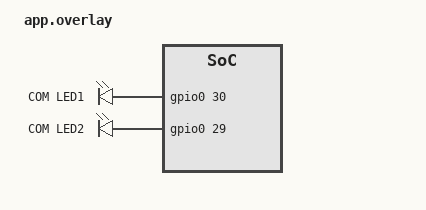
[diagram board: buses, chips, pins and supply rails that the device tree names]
/ {
    chosen {
        zephyr,sram = &sram0;
        zephyr,flash = &flash0;
        /* No console chosen — matches CONFIG_CONSOLE=n */
    };

    aliases {
        led0 = &com_led1;
        led1 = &com_led2;
    };

    leds {
        compatible = "gpio-leds";
        com_led1: com_led_0 {
            gpios = <&gpio0 30 GPIO_ACTIVE_HIGH>;
            label = "COM LED1";
        };
        com_led2: com_led_1 {
            gpios = <&gpio0 29 GPIO_ACTIVE_HIGH>;
            label = "COM LED2";
        };
    };
};

/* Disable board default LEDs if nrf52833dk board file defines them */
/ {
    aliases {
        /* Override any board-level led aliases */
    };
};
